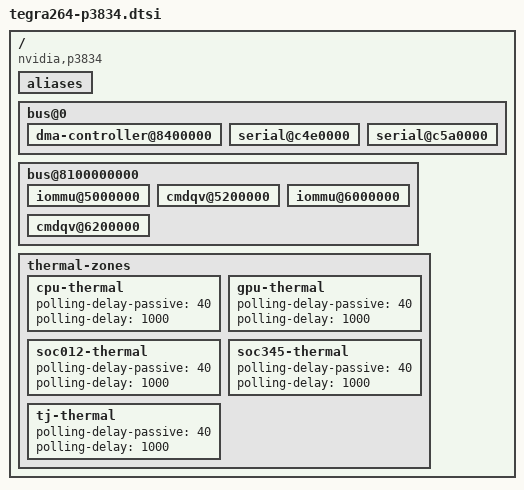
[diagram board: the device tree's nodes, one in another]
// SPDX-License-Identifier: GPL-2.0-only OR BSD-2-Clause

#include "tegra264.dtsi"

/ {
	compatible = "nvidia,p3834", "nvidia,tegra264";

	aliases {
	};

	bus@0 {
		dma-controller@8400000 {
			status = "okay";
		};

		serial@c4e0000 {
			status = "okay";
		};

		serial@c5a0000 {
			status = "okay";
		};
	};

	bus@8100000000 {
		iommu@5000000 {
			status = "okay";
		};

		cmdqv@5200000 {
			status = "okay";
		};

		iommu@6000000 {
			status = "okay";
		};

		cmdqv@6200000 {
			status = "okay";
		};
	};

	thermal-zones {
		cpu-thermal {
			polling-delay-passive = <40>;
			polling-delay = <1000>;
			status = "okay";
		};

		gpu-thermal {
			polling-delay-passive = <40>;
			polling-delay = <1000>;
			status = "okay";
		};

		soc012-thermal {
			polling-delay-passive = <40>;
			polling-delay = <1000>;
			status = "okay";
		};

		soc345-thermal {
			polling-delay-passive = <40>;
			polling-delay = <1000>;
			status = "okay";
		};

		tj-thermal {
			polling-delay-passive = <40>;
			polling-delay = <1000>;
			status = "okay";
		};
	};
};
